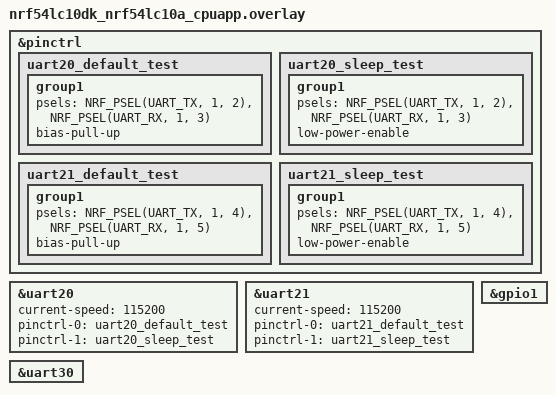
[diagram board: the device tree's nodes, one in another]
/*
 * Copyright (c) 2026 Nordic Semiconductor ASA
 *
 * SPDX-License-Identifier: LicenseRef-Nordic-5-Clause
 */

&pinctrl {
	uart20_default_test: uart20_default_test {
		group1 {
			psels = <NRF_PSEL(UART_TX, 1, 2)>,
				<NRF_PSEL(UART_RX, 1, 3)>;
			bias-pull-up;
		};
	};

	uart20_sleep_test: uart20_sleep_test {
		group1 {
			psels = <NRF_PSEL(UART_TX, 1, 2)>,
				<NRF_PSEL(UART_RX, 1, 3)>;
			low-power-enable;
		};
	};

	uart21_default_test: uart21_default_test {
		group1 {
			psels = <NRF_PSEL(UART_TX, 1, 4)>,
				<NRF_PSEL(UART_RX, 1, 5)>;
			bias-pull-up;
		};
	};

	uart21_sleep_test: uart21_sleep_test {
		group1 {
			psels = <NRF_PSEL(UART_TX, 1, 4)>,
				<NRF_PSEL(UART_RX, 1, 5)>;
			low-power-enable;
		};
	};
};

&uart20 {
	status = "okay";
	current-speed = <115200>;
	pinctrl-0 = <&uart20_default_test>;
	pinctrl-1 = <&uart20_sleep_test>;
	pinctrl-names = "default", "sleep";
};

&uart21 {
	status = "okay";
	current-speed = <115200>;
	pinctrl-0 = <&uart21_default_test>;
	pinctrl-1 = <&uart21_sleep_test>;
	pinctrl-names = "default", "sleep";
};

&uart30 {
	status = "okay";
};

&gpio1 {
	status = "okay";
};
